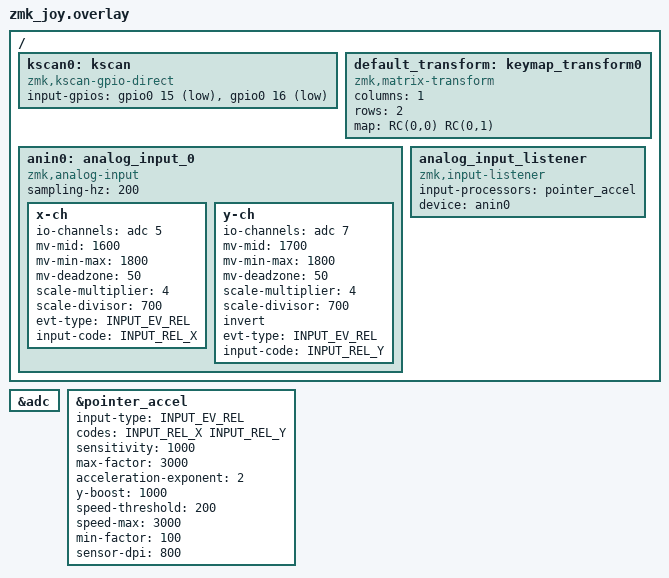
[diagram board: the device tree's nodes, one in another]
#include <dt-bindings/zmk/matrix_transform.h>
#include <zephyr/dt-bindings/input/input-event-codes.h>
#include <input/processors.dtsi>
#include <dt-bindings/zmk/input_transform.h>
#include <zephyr/dt-bindings/input/input-event-codes.h>
#include <behaviors/input_gestures_accel.dtsi>

&adc {
	status = "okay";
};

&pointer_accel {
    input-type = <INPUT_EV_REL>;
    codes = <INPUT_REL_X INPUT_REL_Y>;
    sensitivity = <1000>;         // 1.2x base sensitivity
    max-factor = <3000>;          // 3.0x maximum acceleration
    acceleration-exponent = <2>;  // Advanced exponential curve (1-5)
    y-boost = <1000>;             // 1.3x Y-axis boost for widescreen
    speed-threshold = <200>;      // Start acceleration at 600 counts/sec
    speed-max = <3000>;           // Max acceleration at 3500 counts/sec
    min-factor = <100>;          // 1.0x minimum (no deceleration)
    sensor-dpi = <800>;           // 800 DPI sensor (optional, defaults to 800)
};

/ {

    kscan0: kscan {
        compatible = "zmk,kscan-gpio-direct";
        input-gpios
            = <&gpio0 15 (GPIO_ACTIVE_LOW | GPIO_PULL_UP)>
            , <&gpio0 16 (GPIO_ACTIVE_LOW | GPIO_PULL_UP)>;
    };
	
	default_transform: keymap_transform0 {
        compatible = "zmk,matrix-transform";
        columns = <1>; // Length of the "col-gpios" array
        rows = <2>; // Length of the "row-gpios" array
        map = <
        //   Key 1 | Key 2 |
            RC(0,0) RC(0,1)
        >;
    };

	anin0: analog_input_0 {
		compatible = "zmk,analog-input";
		sampling-hz = <200>;
		x-ch {
			io-channels = <&adc 5>; // <--- see ain-map.png for nRF52840 5 or 10
			mv-mid = <1600>;
			mv-min-max = <1800>;
			mv-deadzone = <50>;
			scale-multiplier = <4>;
			scale-divisor = <700>;
			evt-type = <INPUT_EV_REL>;
			input-code = <INPUT_REL_X>;
		};
		y-ch {
			io-channels = <&adc 7>; // <--- see ain-map.png for nRF52840 7 or 8
			mv-mid = <1700>;
			mv-min-max = <1800>;
			mv-deadzone = <50>;
			scale-multiplier = <4>;
			scale-divisor = <700>;
			invert;
			evt-type = <INPUT_EV_REL>;
			input-code = <INPUT_REL_Y>;

		};
	};
	

	
	    analog_input_listener {
        status = "okay";
		input-processors = <&pointer_accel>;
        compatible = "zmk,input-listener";
        device = <&anin0>;

    };
	
};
